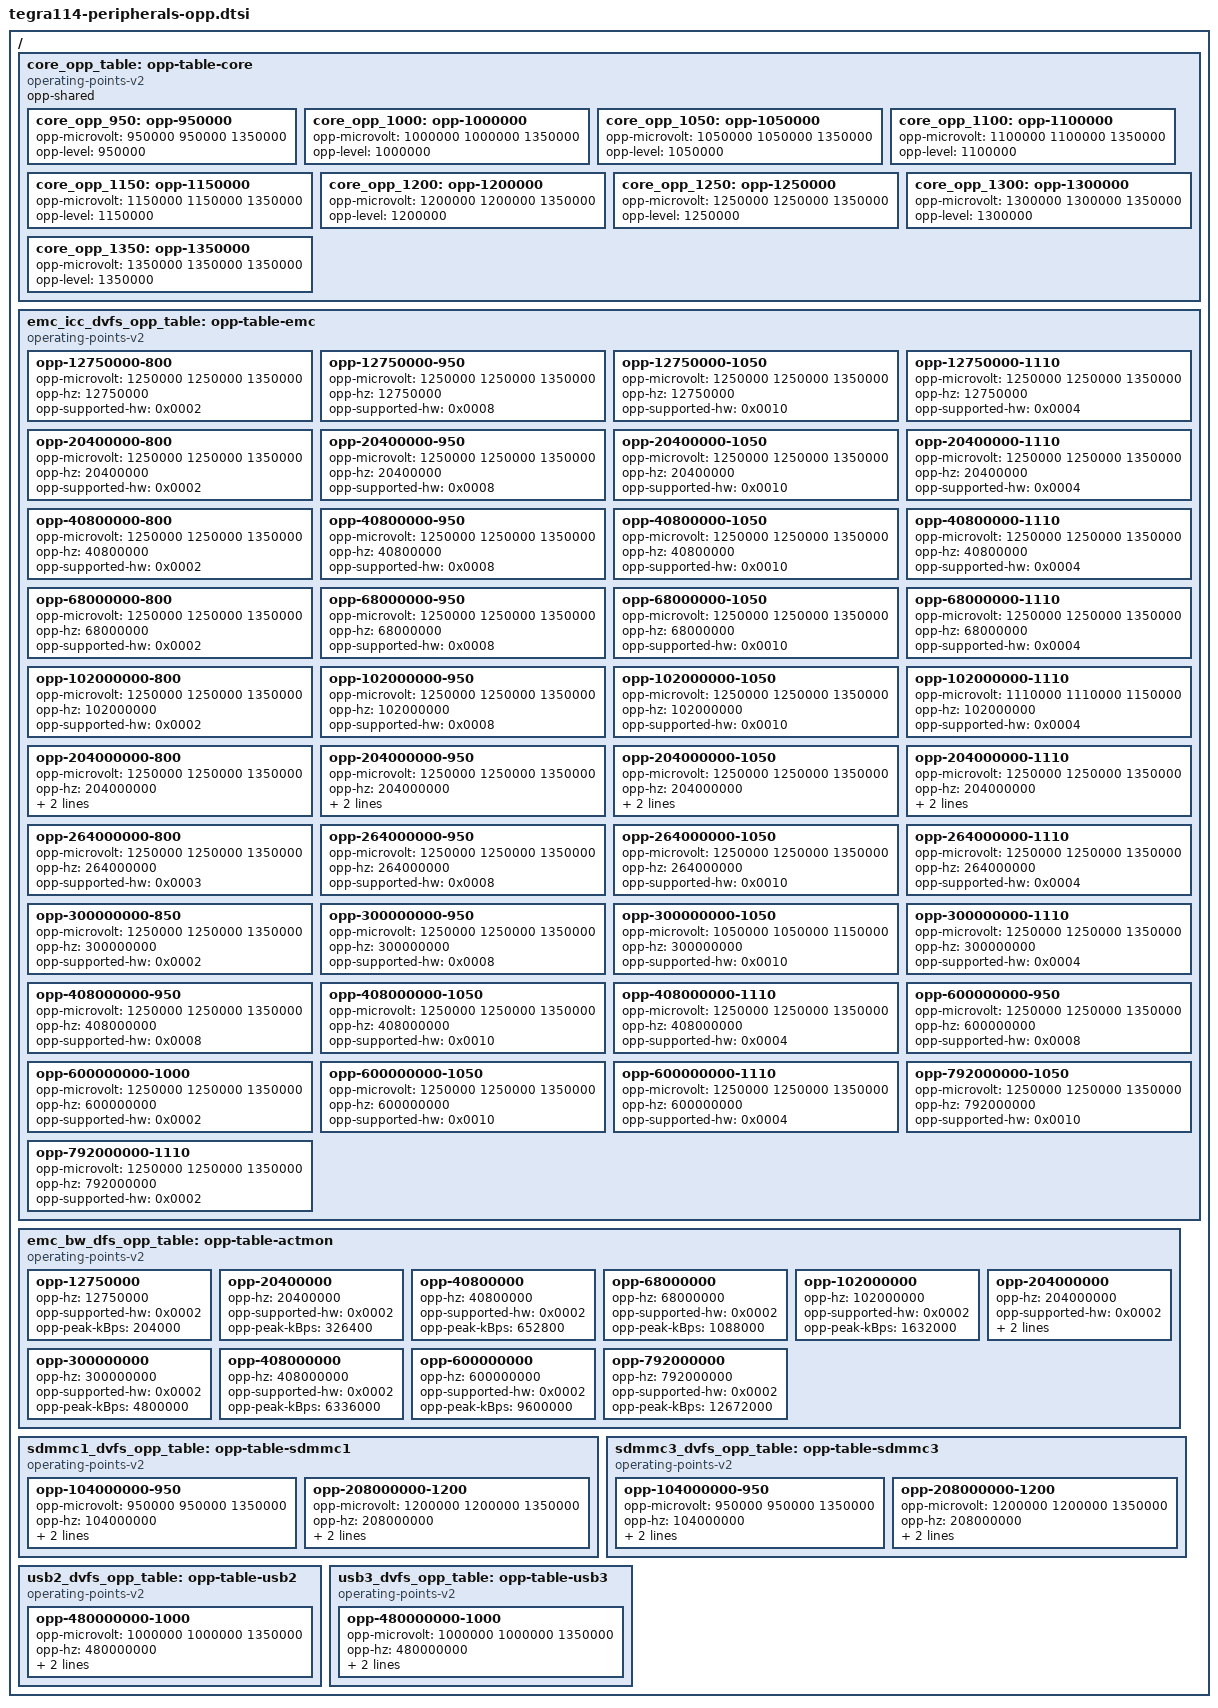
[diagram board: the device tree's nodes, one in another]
// SPDX-License-Identifier: GPL-2.0

/ {

	core_opp_table: opp-table-core {
		compatible = "operating-points-v2";
		opp-shared;

		core_opp_950: opp-950000 {
			opp-microvolt = <950000 950000 1350000>;
			opp-level = <950000>;
		};

		core_opp_1000: opp-1000000 {
			opp-microvolt = <1000000 1000000 1350000>;
			opp-level = <1000000>;
		};

		core_opp_1050: opp-1050000 {
			opp-microvolt = <1050000 1050000 1350000>;
			opp-level = <1050000>;
		};

		core_opp_1100: opp-1100000 {
			opp-microvolt = <1100000 1100000 1350000>;
			opp-level = <1100000>;
		};

		core_opp_1150: opp-1150000 {
			opp-microvolt = <1150000 1150000 1350000>;
			opp-level = <1150000>;
		};

		core_opp_1200: opp-1200000 {
			opp-microvolt = <1200000 1200000 1350000>;
			opp-level = <1200000>;
		};

		core_opp_1250: opp-1250000 {
			opp-microvolt = <1250000 1250000 1350000>;
			opp-level = <1250000>;
		};

		core_opp_1300: opp-1300000 {
			opp-microvolt = <1300000 1300000 1350000>;
			opp-level = <1300000>;
		};

		core_opp_1350: opp-1350000 {
			opp-microvolt = <1350000 1350000 1350000>;
			opp-level = <1350000>;
		};
	};

	emc_icc_dvfs_opp_table: opp-table-emc {
		compatible = "operating-points-v2";

		opp-12750000-800 {
			opp-microvolt = <1250000 1250000 1350000>;
			opp-hz = /bits/ 64 <12750000>;
			opp-supported-hw = <0x0002>;
		};

		opp-12750000-950 {
                        opp-microvolt = <1250000 1250000 1350000>;
			opp-hz = /bits/ 64 <12750000>;
			opp-supported-hw = <0x0008>;
		};

		opp-12750000-1050 {
                        opp-microvolt = <1250000 1250000 1350000>;
			opp-hz = /bits/ 64 <12750000>;
			opp-supported-hw = <0x0010>;
		};

		opp-12750000-1110 {
                        opp-microvolt = <1250000 1250000 1350000>;
			opp-hz = /bits/ 64 <12750000>;
			opp-supported-hw = <0x0004>;
		};

		opp-20400000-800 {
                        opp-microvolt = <1250000 1250000 1350000>;
			opp-hz = /bits/ 64 <20400000>;
			opp-supported-hw = <0x0002>;
		};

		opp-20400000-950 {
                        opp-microvolt = <1250000 1250000 1350000>;
			opp-hz = /bits/ 64 <20400000>;
			opp-supported-hw = <0x0008>;
		};

		opp-20400000-1050 {
                        opp-microvolt = <1250000 1250000 1350000>;
			opp-hz = /bits/ 64 <20400000>;
			opp-supported-hw = <0x0010>;
		};

		opp-20400000-1110 {
                        opp-microvolt = <1250000 1250000 1350000>;
			opp-hz = /bits/ 64 <20400000>;
			opp-supported-hw = <0x0004>;
		};

		opp-40800000-800 {
			opp-microvolt = <1250000 1250000 1350000>;
			opp-hz = /bits/ 64 <40800000>;
			opp-supported-hw = <0x0002>;
		};

		opp-40800000-950 {
                        opp-microvolt = <1250000 1250000 1350000>;
			opp-hz = /bits/ 64 <40800000>;
			opp-supported-hw = <0x0008>;
		};

		opp-40800000-1050 {
                        opp-microvolt = <1250000 1250000 1350000>;
			opp-hz = /bits/ 64 <40800000>;
			opp-supported-hw = <0x0010>;
		};

		opp-40800000-1110 {
                        opp-microvolt = <1250000 1250000 1350000>;
			opp-hz = /bits/ 64 <40800000>;
			opp-supported-hw = <0x0004>;
		};

		opp-68000000-800 {
			opp-microvolt = <1250000 1250000 1350000>;
			opp-hz = /bits/ 64 <68000000>;
			opp-supported-hw = <0x0002>;
		};

		opp-68000000-950 {
                        opp-microvolt = <1250000 1250000 1350000>;
			opp-hz = /bits/ 64 <68000000>;
			opp-supported-hw = <0x0008>;
		};

		opp-68000000-1050 {
                        opp-microvolt = <1250000 1250000 1350000>;
			opp-hz = /bits/ 64 <68000000>;
			opp-supported-hw = <0x0010>;
		};

		opp-68000000-1110 {
                        opp-microvolt = <1250000 1250000 1350000>;
			opp-hz = /bits/ 64 <68000000>;
			opp-supported-hw = <0x0004>;
		};

		opp-102000000-800 {
			opp-microvolt = <1250000 1250000 1350000>;
			opp-hz = /bits/ 64 <102000000>;
			opp-supported-hw = <0x0002>;
		};

		opp-102000000-950 {
                        opp-microvolt = <1250000 1250000 1350000>;
			opp-hz = /bits/ 64 <102000000>;
			opp-supported-hw = <0x0008>;
		};

		opp-102000000-1050 {
                        opp-microvolt = <1250000 1250000 1350000>;
			opp-hz = /bits/ 64 <102000000>;
			opp-supported-hw = <0x0010>;
		};

		opp-102000000-1110 {
			opp-microvolt = <1110000 1110000 1150000>;
			opp-hz = /bits/ 64 <102000000>;
			opp-supported-hw = <0x0004>;
		};

		opp-204000000-800 {
			opp-microvolt = <1250000 1250000 1350000>;
			opp-hz = /bits/ 64 <204000000>;
			opp-supported-hw = <0x0002>;
			opp-suspend;
		};

		opp-204000000-950 {
                        opp-microvolt = <1250000 1250000 1350000>;
			opp-hz = /bits/ 64 <204000000>;
			opp-supported-hw = <0x0008>;
			opp-suspend;
		};

		opp-204000000-1050 {
                        opp-microvolt = <1250000 1250000 1350000>;
			opp-hz = /bits/ 64 <204000000>;
			opp-supported-hw = <0x0010>;
			opp-suspend;
		};

		opp-204000000-1110 {
                        opp-microvolt = <1250000 1250000 1350000>;
			opp-hz = /bits/ 64 <204000000>;
			opp-supported-hw = <0x0004>;
			opp-suspend;
		};

		opp-264000000-800 {
                        opp-microvolt = <1250000 1250000 1350000>;
			opp-hz = /bits/ 64 <264000000>;
			opp-supported-hw = <0x0003>;
		};

		opp-264000000-950 {
                        opp-microvolt = <1250000 1250000 1350000>;
			opp-hz = /bits/ 64 <264000000>;
			opp-supported-hw = <0x0008>;
		};

		opp-264000000-1050 {
                        opp-microvolt = <1250000 1250000 1350000>;
			opp-hz = /bits/ 64 <264000000>;
			opp-supported-hw = <0x0010>;
		};

		opp-264000000-1110 {
                        opp-microvolt = <1250000 1250000 1350000>;
			opp-hz = /bits/ 64 <264000000>;
			opp-supported-hw = <0x0004>;
		};

		opp-300000000-850 {
			opp-microvolt = <1250000 1250000 1350000>;
			opp-hz = /bits/ 64 <300000000>;
			opp-supported-hw = <0x0002>;
		};

		opp-300000000-950 {
                        opp-microvolt = <1250000 1250000 1350000>;
			opp-hz = /bits/ 64 <300000000>;
			opp-supported-hw = <0x0008>;
		};

		opp-300000000-1050 {
			opp-microvolt = <1050000 1050000 1150000>;
			opp-hz = /bits/ 64 <300000000>;
			opp-supported-hw = <0x0010>;
		};

		opp-300000000-1110 {
                        opp-microvolt = <1250000 1250000 1350000>;
			opp-hz = /bits/ 64 <300000000>;
			opp-supported-hw = <0x0004>;
		};

		opp-408000000-950 {
                        opp-microvolt = <1250000 1250000 1350000>;
			opp-hz = /bits/ 64 <408000000>;
			opp-supported-hw = <0x0008>;
		};

		opp-408000000-1050 {
                        opp-microvolt = <1250000 1250000 1350000>;
			opp-hz = /bits/ 64 <408000000>;
			opp-supported-hw = <0x0010>;
		};

		opp-408000000-1110 {
                        opp-microvolt = <1250000 1250000 1350000>;
			opp-hz = /bits/ 64 <408000000>;
			opp-supported-hw = <0x0004>;
		};

		opp-600000000-950 {
                        opp-microvolt = <1250000 1250000 1350000>;
			opp-hz = /bits/ 64 <600000000>;
			opp-supported-hw = <0x0008>;
		};

		opp-600000000-1000 {
			opp-microvolt = <1250000 1250000 1350000>;
			opp-hz = /bits/ 64 <600000000>;
			opp-supported-hw = <0x0002>;
		};

		opp-600000000-1050 {
                        opp-microvolt = <1250000 1250000 1350000>;
			opp-hz = /bits/ 64 <600000000>;
			opp-supported-hw = <0x0010>;
		};

		opp-600000000-1110 {
                        opp-microvolt = <1250000 1250000 1350000>;
			opp-hz = /bits/ 64 <600000000>;
			opp-supported-hw = <0x0004>;
		};

//		opp-792000000-1000 {
//			opp-microvolt = <1000000 1000000 1150000>;
//			opp-hz = /bits/ 64 <792000000>;
//			opp-supported-hw = <0x000B>;
//		};

		opp-792000000-1050 {
                        opp-microvolt = <1250000 1250000 1350000>;
			opp-hz = /bits/ 64 <792000000>;
			opp-supported-hw = <0x0010>;
		};

		opp-792000000-1110 {
			opp-microvolt = <1250000 1250000 1350000>;
			opp-hz = /bits/ 64 <792000000>;
			opp-supported-hw = <0x0002>;
		};

//		opp-924000000-1100 {
//			opp-microvolt = <1100000 1100000 1150000>;
//			opp-hz = /bits/ 64 <924000000>;
//			opp-supported-hw = <0x0013>;
//		};

//		opp-1200000000-1100 {
//			opp-microvolt = <1100000 1100000 1150000>;
//			opp-hz = /bits/ 64 <1200000000>;
//			opp-supported-hw = <0x0002>;
//		};
	};

	emc_bw_dfs_opp_table: opp-table-actmon {
		compatible = "operating-points-v2";

		opp-12750000 {
			opp-hz = /bits/ 64 <12750000>;
			opp-supported-hw = <0x0002>;
			opp-peak-kBps = <204000>;
		};

		opp-20400000 {
			opp-hz = /bits/ 64 <20400000>;
			opp-supported-hw = <0x0002>;
			opp-peak-kBps = <326400>;
		};

		opp-40800000 {
			opp-hz = /bits/ 64 <40800000>;
			opp-supported-hw = <0x0002>;
			opp-peak-kBps = <652800>;
		};

		opp-68000000 {
			opp-hz = /bits/ 64 <68000000>;
			opp-supported-hw = <0x0002>;
			opp-peak-kBps = <1088000>;
		};

		opp-102000000 {
			opp-hz = /bits/ 64 <102000000>;
			opp-supported-hw = <0x0002>;
			opp-peak-kBps = <1632000>;
		};

		opp-204000000 {
			opp-hz = /bits/ 64 <204000000>;
			opp-supported-hw = <0x0002>;
			opp-peak-kBps = <3264000>;
			opp-suspend;
		};

		opp-300000000 {
			opp-hz = /bits/ 64 <300000000>;
			opp-supported-hw = <0x0002>;
			opp-peak-kBps = <4800000>;
		};

		opp-408000000 {
			opp-hz = /bits/ 64 <408000000>;
			opp-supported-hw = <0x0002>;
			opp-peak-kBps = <6336000>;
		};

		opp-600000000 {
			opp-hz = /bits/ 64 <600000000>;
			opp-supported-hw = <0x0002>;
			opp-peak-kBps = <9600000>;
		};

		opp-792000000 {
			opp-hz = /bits/ 64 <792000000>;
			opp-supported-hw = <0x0002>;
			opp-peak-kBps = <12672000>;
		};

//		opp-924000000 {
//			opp-hz = /bits/ 64 <924000000>;
//			opp-supported-hw = <0x0013>;
//			opp-peak-kBps = <14784000>;
//		};

//		opp-1200000000 {
//			opp-hz = /bits/ 64 <1200000000>;
//			opp-supported-hw = <0x0003>;
//			opp-peak-kBps = <19200000>;
//		};
	};


	sdmmc1_dvfs_opp_table: opp-table-sdmmc1 {
		compatible = "operating-points-v2";

		opp-104000000-950 {
			opp-microvolt = <950000 950000 1350000>;
			opp-hz = /bits/ 64 <104000000>;
			opp-supported-hw = <0x0002>;
			required-opps = <&core_opp_950>;
		};

		opp-208000000-1200 {
			opp-microvolt = <1200000 1200000 1350000>;
			opp-hz = /bits/ 64 <208000000>;
			opp-supported-hw = <0x0002>;
			required-opps = <&core_opp_1200>;
		};
	};

	sdmmc3_dvfs_opp_table: opp-table-sdmmc3 {
		compatible = "operating-points-v2";

		opp-104000000-950 {
			opp-microvolt = <950000 950000 1350000>;
			opp-hz = /bits/ 64 <104000000>;
			opp-supported-hw = <0x0002>;
			required-opps = <&core_opp_950>;
		};

		opp-208000000-1200 {
			opp-microvolt = <1200000 1200000 1350000>;
			opp-hz = /bits/ 64 <208000000>;
			opp-supported-hw = <0x0002>;
			required-opps = <&core_opp_1200>;
		};
	};

	usb2_dvfs_opp_table: opp-table-usb2 {
		compatible = "operating-points-v2";

		opp-480000000-1000 {
			opp-microvolt = <1000000 1000000 1350000>;
			opp-hz = /bits/ 64 <480000000>;
			opp-supported-hw = <0x0002>;
			required-opps = <&core_opp_1000>;
		};
	};

	usb3_dvfs_opp_table: opp-table-usb3 {
		compatible = "operating-points-v2";

		opp-480000000-1000 {
			opp-microvolt = <1000000 1000000 1350000>;
			opp-hz = /bits/ 64 <480000000>;
			opp-supported-hw = <0x0002>;
			required-opps = <&core_opp_1000>;
		};
	};

};
